# MKL43Z4 register map
Vendor: Freescale Semiconductor, Inc.; Series: Kinetis_L; File version: 1.6
CPU: CM0PLUS r0p0, little endian, no MPU, no FPU, VTOR, 2 interrupt priority bits
Registers are 8-bit, read-write, reset 0x0 unless marked. A register's access mark holds for its fields unless they carry their own. Offsets are from the block's base; [hi:lo] are bit positions; {n}, {i} and the like mark numbered series.

## DMAMUX0 — DMA channel multiplexor
Base 0x40021000; register names take the prefix DMAMUX0_
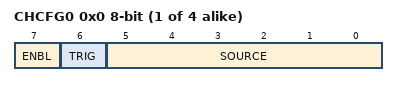
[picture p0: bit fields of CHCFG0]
{0x0+i} CHCFG{i} (i=0..3) — Channel Configuration register
  [7] ENBL — DMA Channel Enable
    0=DMA channel is disabled. This mode is primarily used during configuration of the DMAMux. The DMA has separate channel enables/disables, which should be used to disable or reconfigure a DMA channel.; 1=DMA channel is enabled
  [6] TRIG — DMA Channel Trigger Enable
    0=Triggering is disabled. If triggering is disabled and ENBL is set, the DMA Channel will simply route the specified source to the DMA channel. (Normal mode); 1=Triggering is enabled. If triggering is enabled and ENBL is set, the DMAMUX is in Periodic Trigger mode.
  [5:0] SOURCE — DMA Channel Source (Slot)

## PIT — Periodic Interrupt Timer
Base 0x40037000; register names take the prefix PIT_
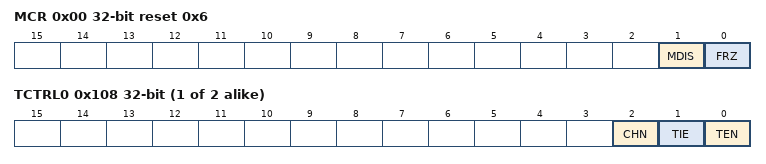
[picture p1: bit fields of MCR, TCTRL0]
0x00 MCR 32-bit reset 0x6 — PIT Module Control Register
  [1] MDIS — Module Disable - (PIT section)
    0=Clock for standard PIT timers is enabled; 1=Clock for standard PIT timers is disabled
  [0] FRZ — Freeze
    0=Timers continue to run in Debug mode; 1=Timers are stopped in Debug mode
0xE0 LTMR64H 32-bit ro — PIT Upper Lifetime Timer Register
  [31:0] LTH — Life Timer value
0xE4 LTMR64L 32-bit ro — PIT Lower Lifetime Timer Register
  [31:0] LTL — Life Timer value
{0x100+0x10*i} LDVAL{i} (i=0..1) 32-bit — Timer Load Value Register
  [31:0] TSV — Timer Start Value
{0x104+0x10*i} CVAL{i} (i=0..1) 32-bit ro — Current Timer Value Register
  [31:0] TVL — Current Timer Value
{0x108+0x10*i} TCTRL{i} (i=0..1) 32-bit — Timer Control Register
  [2] CHN — Chain Mode
    0=Timer is not chained; 1=Timer is chained to previous timer. For example, for Channel 2, if this field is set, Timer 2 is chained to Timer 1.
  [1] TIE — Timer Interrupt Enable
    0=Interrupt requests from Timer n are disabled; 1=Interrupt will be requested whenever TIF is set
  [0] TEN — Timer Enable
    0=Timer n is disabled; 1=Timer n is enabled
{0x10C+0x10*i} TFLG{i} (i=0..1) 32-bit — Timer Flag Register
  [0] TIF — Timer Interrupt Flag
    0=Timeout has not yet occurred; 1=Timeout has occurred

## DAC0 — 12-Bit Digital-to-Analog Converter
Base 0x4003F000; register names take the prefix DAC0_
{0x0+2i} DAT{i}L (i=0..1) — DAC Data Low Register
  [7:0] DATA0
{0x1+2i} DAT{i}H (i=0..1) — DAC Data High Register
  [3:0] DATA1
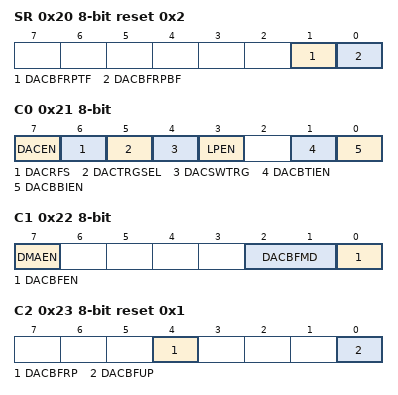
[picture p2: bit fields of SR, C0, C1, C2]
0x20 SR reset 0x2 — DAC Status Register
  [1] DACBFRPTF — DAC Buffer Read Pointer Top Position Flag
    0=The DAC buffer read pointer is not zero; 1=The DAC buffer read pointer is zero
  [0] DACBFRPBF — DAC Buffer Read Pointer Bottom Position Flag
    0=The DAC buffer read pointer is not equal to C2[DACBFUP]; 1=The DAC buffer read pointer is equal to C2[DACBFUP]
0x21 C0 — DAC Control Register
  [7] DACEN — DAC Enable
    0=The DAC system is disabled; 1=The DAC system is enabled
  [6] DACRFS — DAC Reference Select
    0=The DAC selects DACREF_1 as the reference voltage; 1=The DAC selects DACREF_2 as the reference voltage
  [5] DACTRGSEL — DAC Trigger Select
    0=The DAC hardware trigger is selected; 1=The DAC software trigger is selected
  [4] DACSWTRG wo — DAC Software Trigger
    0=The DAC soft trigger is not valid; 1=The DAC soft trigger is valid
  [3] LPEN — DAC Low Power Control
    0=High-Power mode; 1=Low-Power mode
  [1] DACBTIEN — DAC Buffer Read Pointer Top Flag Interrupt Enable
    0=The DAC buffer read pointer top flag interrupt is disabled; 1=The DAC buffer read pointer top flag interrupt is enabled
  [0] DACBBIEN — DAC Buffer Read Pointer Bottom Flag Interrupt Enable
    0=The DAC buffer read pointer bottom flag interrupt is disabled; 1=The DAC buffer read pointer bottom flag interrupt is enabled
0x22 C1 — DAC Control Register 1
  [7] DMAEN — DMA Enable Select
    0=DMA is disabled; 1=DMA is enabled. When DMA is enabled, the DMA request will be generated by original interrupts. The interrupts will not be presented on this module at the same time.
  [2:1] DACBFMD — DAC Buffer Work Mode Select
    0=Normal mode; 2=One-Time Scan mode; 3=FIFO mode
  [0] DACBFEN — DAC Buffer Enable
    0=Buffer read pointer is disabled. The converted data is always the first word of the buffer.; 1=Buffer read pointer is enabled. The converted data is the word that the read pointer points to. It means converted data can be from any word of the buffer.
0x23 C2 reset 0x1 — DAC Control Register 2
  [4] DACBFRP — DAC Buffer Read Pointer
  [0] DACBFUP — DAC Buffer Upper Limit

## Notices in the file
Redistribution and use in source and binary forms, with or without modification,
are permitted provided that the following conditions are met:
o Redistributions of source code must retain the above copyright notice, this list
of conditions and the following disclaimer.
o Redistributions in binary form must reproduce the above copyright notice, this
list of conditions and the following disclaimer in the documentation and/or
other materials provided with the distribution.
o Neither the name of Freescale Semiconductor, Inc. nor the names of its
contributors may be used to endorse or promote products derived from this
software without specific prior written permission.
THIS SOFTWARE IS PROVIDED BY THE COPYRIGHT HOLDERS AND CONTRIBUTORS "AS IS" AND
ANY EXPRESS OR IMPLIED WARRANTIES, INCLUDING, BUT NOT LIMITED TO, THE IMPLIED
WARRANTIES OF MERCHANTABILITY AND FITNESS FOR A PARTICULAR PURPOSE ARE
DISCLAIMED. IN NO EVENT SHALL THE COPYRIGHT HOLDER OR CONTRIBUTORS BE LIABLE FOR
ANY DIRECT, INDIRECT, INCIDENTAL, SPECIAL, EXEMPLARY, OR CONSEQUENTIAL DAMAGES
(INCLUDING, BUT NOT LIMITED TO, PROCUREMENT OF SUBSTITUTE GOODS OR SERVICES;
LOSS OF USE, DATA, OR PROFITS; OR BUSINESS INTERRUPTION) HOWEVER CAUSED AND ON
ANY THEORY OF LIABILITY, WHETHER IN CONTRACT, STRICT LIABILITY, OR TORT
(INCLUDING NEGLIGENCE OR OTHERWISE) ARISING IN ANY WAY OUT OF THE USE OF THIS
SOFTWARE, EVEN IF ADVISED OF THE POSSIBILITY OF SUCH DAMAGE.
